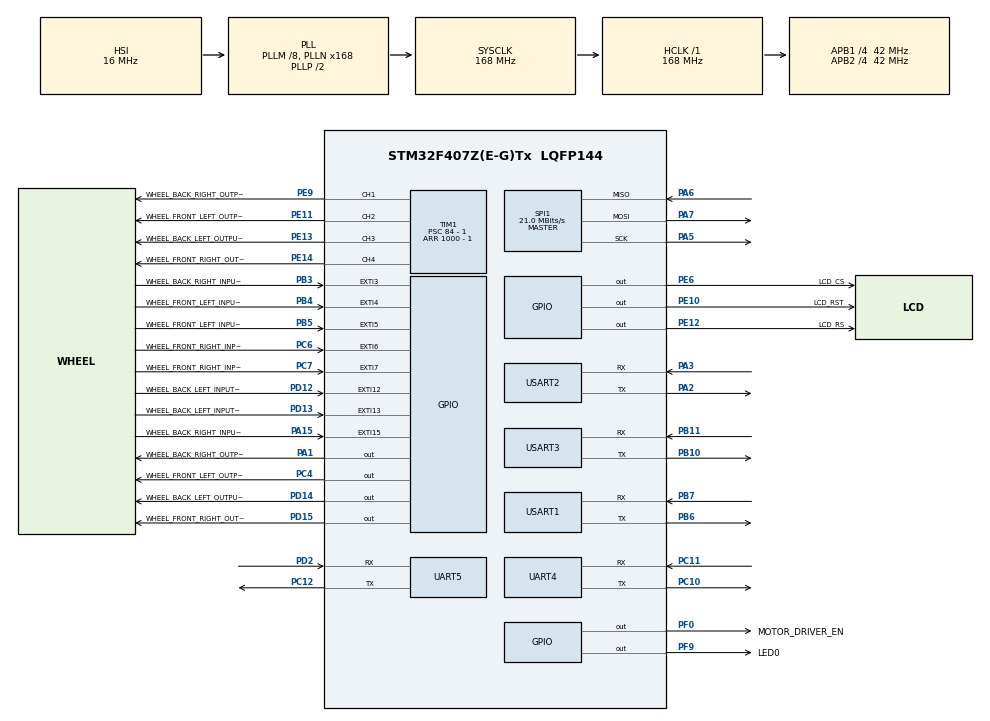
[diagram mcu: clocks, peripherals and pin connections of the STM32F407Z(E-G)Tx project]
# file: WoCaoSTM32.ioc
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Mcu.Family=STM32F4
Mcu.Name=STM32F407Z(E-G)Tx
Mcu.Package=LQFP144
NVIC.EXTI15_10_IRQn=true\:1\:0\:true\:false\:true\:true\:true
NVIC.EXTI3_IRQn=true\:1\:0\:true\:false\:true\:true\:true
NVIC.EXTI4_IRQn=true\:1\:0\:true\:false\:true\:true\:true
NVIC.EXTI9_5_IRQn=true\:1\:0\:true\:false\:true\:true\:true
NVIC.PriorityGroup=NVIC_PRIORITYGROUP_4
NVIC.TIM6_DAC_IRQn=true\:0\:0\:false\:false\:true\:true\:true
NVIC.UART4_IRQn=true\:1\:0\:true\:false\:true\:true\:true
NVIC.UART5_IRQn=true\:1\:0\:true\:false\:true\:true\:true
NVIC.USART1_IRQn=true\:1\:0\:true\:false\:true\:true\:true
NVIC.USART2_IRQn=true\:1\:0\:true\:false\:true\:true\:true
NVIC.USART3_IRQn=true\:0\:0\:false\:false\:true\:true\:true
PA1.GPIO_Label=WHEEL_BACK_RIGHT_OUTPUT_B
PA1.GPIO_Speed=GPIO_SPEED_FREQ_VERY_HIGH
PA1.Signal=GPIO_Output
PA13.Mode=Serial_Wire
PA13.Signal=SYS_JTMS-SWDIO
PA14.Mode=Serial_Wire
PA14.Signal=SYS_JTCK-SWCLK
PA15.GPIO_Label=WHEEL_BACK_RIGHT_INPUT_A
PA15.GPIO_ModeDefaultEXTI=GPIO_MODE_IT_RISING_FALLING
PA15.Signal=GPXTI15
PA2.Mode=Asynchronous
PA2.Signal=USART2_TX
PA3.Mode=Asynchronous
PA3.Signal=USART2_RX
PA5.Mode=Full_Duplex_Master
PA5.Signal=SPI1_SCK
PA6.Mode=Full_Duplex_Master
PA6.Signal=SPI1_MISO
PA7.Mode=Full_Duplex_Master
PA7.Signal=SPI1_MOSI
PB10.Mode=Asynchronous
PB10.Signal=USART3_TX
PB11.Mode=Asynchronous
PB11.Signal=USART3_RX
PB3.GPIO_Label=WHEEL_BACK_RIGHT_INPUT_B
PB3.GPIO_ModeDefaultEXTI=GPIO_MODE_IT_RISING_FALLING
PB3.Signal=GPXTI3
PB4.GPIO_Label=WHEEL_FRONT_LEFT_INPUT_A
PB4.GPIO_ModeDefaultEXTI=GPIO_MODE_IT_RISING_FALLING
PB4.GPIO_PuPd=GPIO_PULLDOWN
PB4.Signal=GPXTI4
PB5.GPIO_Label=WHEEL_FRONT_LEFT_INPUT_B
PB5.GPIO_ModeDefaultEXTI=GPIO_MODE_IT_RISING_FALLING
PB5.GPIO_PuPd=GPIO_PULLDOWN
PB5.Signal=GPXTI5
PB6.Mode=Asynchronous
PB6.Signal=USART1_TX
PB7.Mode=Asynchronous
PB7.Signal=USART1_RX
PC10.Mode=Asynchronous
PC10.Signal=UART4_TX
PC11.Mode=Asynchronous
PC11.Signal=UART4_RX
PC12.Mode=Asynchronous
PC12.Signal=UART5_TX
PC4.GPIO_Label=WHEEL_FRONT_LEFT_OUTPUT_B
PC4.GPIO_Speed=GPIO_SPEED_FREQ_VERY_HIGH
PC4.Signal=GPIO_Output
PC6.GPIO_Label=WHEEL_FRONT_RIGHT_INPUT_A
PC6.GPIO_ModeDefaultEXTI=GPIO_MODE_IT_RISING_FALLING
PC6.GPIO_PuPd=GPIO_PULLDOWN
PC6.Signal=GPXTI6
PC7.GPIO_Label=WHEEL_FRONT_RIGHT_INPUT_B
PC7.GPIO_ModeDefaultEXTI=GPIO_MODE_IT_RISING_FALLING
PC7.GPIO_PuPd=GPIO_PULLDOWN
PC7.Signal=GPXTI7
PD12.GPIO_Label=WHEEL_BACK_LEFT_INPUT_A
PD12.GPIO_ModeDefaultEXTI=GPIO_MODE_IT_RISING_FALLING
PD12.GPIO_PuPd=GPIO_PULLDOWN
PD12.Signal=GPXTI12
PD13.GPIO_Label=WHEEL_BACK_LEFT_INPUT_B
PD13.GPIO_ModeDefaultEXTI=GPIO_MODE_IT_RISING_FALLING
PD13.GPIO_PuPd=GPIO_PULLDOWN
PD13.Signal=GPXTI13
PD14.GPIO_Label=WHEEL_BACK_LEFT_OUTPUT_B
PD14.GPIO_Speed=GPIO_SPEED_FREQ_VERY_HIGH
PD14.Signal=GPIO_Output
PD15.GPIO_Label=WHEEL_FRONT_RIGHT_OUTPUT_B
PD15.GPIO_Speed=GPIO_SPEED_FREQ_VERY_HIGH
PD15.Signal=GPIO_Output
PD2.Mode=Asynchronous
PD2.Signal=UART5_RX
PE10.GPIO_Label=LCD_RST
PE10.GPIO_Speed=GPIO_SPEED_FREQ_VERY_HIGH
PE10.Signal=GPIO_Output
PE11.GPIO_Label=WHEEL_FRONT_LEFT_OUTPUT_A
PE11.GPIO_Speed=GPIO_SPEED_FREQ_VERY_HIGH
PE11.Signal=S_TIM1_CH2
PE12.GPIO_Label=LCD_RS
PE12.GPIO_Speed=GPIO_SPEED_FREQ_VERY_HIGH
PE12.Signal=GPIO_Output
PE13.GPIO_Label=WHEEL_BACK_LEFT_OUTPUT_A
PE13.GPIO_Speed=GPIO_SPEED_FREQ_VERY_HIGH
PE13.Signal=S_TIM1_CH3
PE14.GPIO_Label=WHEEL_FRONT_RIGHT_OUTPUT_A
PE14.GPIO_Speed=GPIO_SPEED_FREQ_VERY_HIGH
PE14.Signal=S_TIM1_CH4
PE6.GPIO_Label=LCD_CS
PE6.GPIO_Speed=GPIO_SPEED_FREQ_VERY_HIGH
PE6.Signal=GPIO_Output
PE9.GPIO_Label=WHEEL_BACK_RIGHT_OUTPUT_A
PE9.GPIO_Speed=GPIO_SPEED_FREQ_VERY_HIGH
PE9.Signal=S_TIM1_CH1
PF0.GPIO_Label=MOTOR_DRIVER_EN
PF0.GPIO_Speed=GPIO_SPEED_FREQ_VERY_HIGH
PF0.Signal=GPIO_Output
PF9.GPIO_Label=LED0
PF9.GPIO_Speed=GPIO_SPEED_FREQ_VERY_HIGH
PF9.Signal=GPIO_Output
PH0-OSC_IN.Mode=HSE-External-Oscillator
PH0-OSC_IN.Signal=RCC_OSC_IN
PH1-OSC_OUT.Mode=HSE-External-Oscillator
PH1-OSC_OUT.Signal=RCC_OSC_OUT
ProjectManager.HeapSize=0x1000
ProjectManager.StackSize=0x1000
ProjectManager.TargetToolchain=STM32CubeIDE
RCC.48MHZClocksFreq_Value=84000000
RCC.AHBFreq_Value=168000000
RCC.APB1CLKDivider=RCC_HCLK_DIV4
RCC.APB1Freq_Value=42000000
RCC.APB1TimFreq_Value=84000000
RCC.APB2CLKDivider=RCC_HCLK_DIV4
RCC.APB2Freq_Value=42000000
RCC.APB2TimFreq_Value=84000000
RCC.CortexFreq_Value=168000000
RCC.HCLKFreq_Value=168000000
RCC.HSE_VALUE=25000000
RCC.HSI_VALUE=16000000
RCC.LSE_VALUE=32768
RCC.PLLM=8
RCC.PLLN=168
RCC.SYSCLKFreq_VALUE=168000000
RCC.SYSCLKSource=RCC_SYSCLKSOURCE_PLLCLK
RCC.VCOOutputFreq_Value=336000000
SH.S_TIM1_CH1.0=TIM1_CH1,PWM Generation1 CH1
SH.S_TIM1_CH2.0=TIM1_CH2,PWM Generation2 CH2
SH.S_TIM1_CH3.0=TIM1_CH3,PWM Generation3 CH3
SH.S_TIM1_CH4.0=TIM1_CH4,PWM Generation4 CH4
SPI1.CalculateBaudRate=21.0 MBits/s
SPI1.Direction=SPI_DIRECTION_2LINES
SPI1.Mode=SPI_MODE_MASTER
SPI1.VirtualType=VM_MASTER
TIM1.Channel-PWM\ Generation1\ CH1=TIM_CHANNEL_1
TIM1.Channel-PWM\ Generation2\ CH2=TIM_CHANNEL_2
TIM1.Channel-PWM\ Generation3\ CH3=TIM_CHANNEL_3
TIM1.Channel-PWM\ Generation4\ CH4=TIM_CHANNEL_4
TIM1.Period=1000 - 1
TIM1.Prescaler=84 - 1
TIM6.Period=1000 - 1
TIM6.Prescaler=84 - 1
UART4.VirtualMode=Asynchronous
UART5.VirtualMode=Asynchronous
USART1.VirtualMode=VM_ASYNC
USART2.VirtualMode=VM_ASYNC
USART3.VirtualMode=VM_ASYNC
VP_TIM1_VS_ClockSourceINT.Mode=Internal
VP_TIM6_VS_ClockSourceINT.Mode=Enable_Timer
board=custom

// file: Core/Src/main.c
/* USER CODE BEGIN Header */
/**
  ******************************************************************************
  * @file           : main.c
  * @brief          : Main program body
  ******************************************************************************
  * @attention
  *
  * Copyright (c) 2023 STMicroelectronics.
  * All rights reserved.
  *
  * This software is licensed under terms that can be found in the LICENSE file
  * in the root directory of this software component.
  * If no LICENSE file comes with this software, it is provided AS-IS.
  *
  ******************************************************************************
  */
#include <stdio.h>
#include <string.h>
#include "RobotMain.h"

/* USER CODE END Header */
#include "main.h"

SPI_HandleTypeDef hspi1;

TIM_HandleTypeDef htim1;
TIM_HandleTypeDef htim6;

UART_HandleTypeDef huart4;
UART_HandleTypeDef huart5;
UART_HandleTypeDef huart1;
UART_HandleTypeDef huart2;
UART_HandleTypeDef huart3;

void SystemClock_Config(void);
static void MX_GPIO_Init(void);
static void MX_TIM1_Init(void);
static void MX_TIM6_Init(void);
static void MX_USART1_UART_Init(void);
static void MX_USART3_UART_Init(void);
static void MX_USART2_UART_Init(void);
static void MX_UART5_Init(void);
static void MX_SPI1_Init(void);
static void MX_UART4_Init(void);

int main(void)
{

  /* MCU Configuration--------------------------------------------------------*/

  /* Reset of all peripherals, Initializes the Flash interface and the Systick. */
  HAL_Init();

  /* Configure the system clock */
  SystemClock_Config();

  /* Initialize all configured peripherals */
  MX_GPIO_Init();
  MX_TIM1_Init();
  MX_TIM6_Init();
  MX_USART1_UART_Init();
  MX_USART3_UART_Init();
  MX_USART2_UART_Init();
  MX_UART5_Init();
  MX_SPI1_Init();
  MX_UART4_Init();
  /* USER CODE BEGIN 2 */

    HAL_Delay(1000);

    RobotMain();

  /* USER CODE END 2 */

  /* Infinite loop */
  /* USER CODE BEGIN WHILE */
  while (1)
  {
      HAL_GPIO_TogglePin(GPIOF, GPIO_PIN_9);
      HAL_Delay(100);

    /* USER CODE END WHILE */

  }
}

void SystemClock_Config(void)
{
  RCC_OscInitTypeDef RCC_OscInitStruct = {0};
  RCC_ClkInitTypeDef RCC_ClkInitStruct = {0};

  /** Configure the main internal regulator output voltage
  */
  __HAL_RCC_PWR_CLK_ENABLE();
  __HAL_PWR_VOLTAGESCALING_CONFIG(PWR_REGULATOR_VOLTAGE_SCALE1);
  /** Initializes the RCC Oscillators according to the specified parameters
  * in the RCC_OscInitTypeDef structure.
  */
  RCC_OscInitStruct.OscillatorType = RCC_OSCILLATORTYPE_HSI;
  RCC_OscInitStruct.HSIState = RCC_HSI_ON;
  RCC_OscInitStruct.HSICalibrationValue = RCC_HSICALIBRATION_DEFAULT;
  RCC_OscInitStruct.PLL.PLLState = RCC_PLL_ON;
  RCC_OscInitStruct.PLL.PLLSource = RCC_PLLSOURCE_HSI;
  RCC_OscInitStruct.PLL.PLLM = 8;
  RCC_OscInitStruct.PLL.PLLN = 168;
  RCC_OscInitStruct.PLL.PLLP = RCC_PLLP_DIV2;
  RCC_OscInitStruct.PLL.PLLQ = 4;
  if (HAL_RCC_OscConfig(&RCC_OscInitStruct) != HAL_OK)
  {
    Error_Handler();
  }
  /** Initializes the CPU, AHB and APB buses clocks
  */
  RCC_ClkInitStruct.ClockType = RCC_CLOCKTYPE_HCLK|RCC_CLOCKTYPE_SYSCLK
                              |RCC_CLOCKTYPE_PCLK1|RCC_CLOCKTYPE_PCLK2;
  RCC_ClkInitStruct.SYSCLKSource = RCC_SYSCLKSOURCE_PLLCLK;
  RCC_ClkInitStruct.AHBCLKDivider = RCC_SYSCLK_DIV1;
  RCC_ClkInitStruct.APB1CLKDivider = RCC_HCLK_DIV4;
  RCC_ClkInitStruct.APB2CLKDivider = RCC_HCLK_DIV4;

  if (HAL_RCC_ClockConfig(&RCC_ClkInitStruct, FLASH_LATENCY_5) != HAL_OK)
  {
    Error_Handler();
  }
}

static void MX_SPI1_Init(void)
{

  /* SPI1 parameter configuration*/
  hspi1.Instance = SPI1;
  hspi1.Init.Mode = SPI_MODE_MASTER;
  hspi1.Init.Direction = SPI_DIRECTION_2LINES;
  hspi1.Init.DataSize = SPI_DATASIZE_8BIT;
  hspi1.Init.CLKPolarity = SPI_POLARITY_LOW;
  hspi1.Init.CLKPhase = SPI_PHASE_1EDGE;
  hspi1.Init.NSS = SPI_NSS_SOFT;
  hspi1.Init.BaudRatePrescaler = SPI_BAUDRATEPRESCALER_2;
  hspi1.Init.FirstBit = SPI_FIRSTBIT_MSB;
  hspi1.Init.TIMode = SPI_TIMODE_DISABLE;
  hspi1.Init.CRCCalculation = SPI_CRCCALCULATION_DISABLE;
  hspi1.Init.CRCPolynomial = 10;
  if (HAL_SPI_Init(&hspi1) != HAL_OK)
  {
    Error_Handler();
  }

}

static void MX_TIM1_Init(void)
{

  TIM_ClockConfigTypeDef sClockSourceConfig = {0};
  TIM_MasterConfigTypeDef sMasterConfig = {0};
  TIM_OC_InitTypeDef sConfigOC = {0};
  TIM_BreakDeadTimeConfigTypeDef sBreakDeadTimeConfig = {0};

  htim1.Instance = TIM1;
  htim1.Init.Prescaler = 84 - 1;
  htim1.Init.CounterMode = TIM_COUNTERMODE_UP;
  htim1.Init.Period = 1000 - 1;
  htim1.Init.ClockDivision = TIM_CLOCKDIVISION_DIV1;
  htim1.Init.RepetitionCounter = 0;
  htim1.Init.AutoReloadPreload = TIM_AUTORELOAD_PRELOAD_DISABLE;
  if (HAL_TIM_Base_Init(&htim1) != HAL_OK)
  {
    Error_Handler();
  }
  sClockSourceConfig.ClockSource = TIM_CLOCKSOURCE_INTERNAL;
  if (HAL_TIM_ConfigClockSource(&htim1, &sClockSourceConfig) != HAL_OK)
  {
    Error_Handler();
  }
  if (HAL_TIM_PWM_Init(&htim1) != HAL_OK)
  {
    Error_Handler();
  }
  sMasterConfig.MasterOutputTrigger = TIM_TRGO_RESET;
  sMasterConfig.MasterSlaveMode = TIM_MASTERSLAVEMODE_DISABLE;
  if (HAL_TIMEx_MasterConfigSynchronization(&htim1, &sMasterConfig) != HAL_OK)
  {
    Error_Handler();
  }
  sConfigOC.OCMode = TIM_OCMODE_PWM1;
  sConfigOC.Pulse = 0;
  sConfigOC.OCPolarity = TIM_OCPOLARITY_HIGH;
  sConfigOC.OCNPolarity = TIM_OCNPOLARITY_HIGH;
  sConfigOC.OCFastMode = TIM_OCFAST_DISABLE;
  sConfigOC.OCIdleState = TIM_OCIDLESTATE_RESET;
  sConfigOC.OCNIdleState = TIM_OCNIDLESTATE_RESET;
  if (HAL_TIM_PWM_ConfigChannel(&htim1, &sConfigOC, TIM_CHANNEL_1) != HAL_OK)
  {
    Error_Handler();
  }
  if (HAL_TIM_PWM_ConfigChannel(&htim1, &sConfigOC, TIM_CHANNEL_2) != HAL_OK)
  {
    Error_Handler();
  }
  if (HAL_TIM_PWM_ConfigChannel(&htim1, &sConfigOC, TIM_CHANNEL_3) != HAL_OK)
  {
    Error_Handler();
  }
  if (HAL_TIM_PWM_ConfigChannel(&htim1, &sConfigOC, TIM_CHANNEL_4) != HAL_OK)
  {
    Error_Handler();
  }
  sBreakDeadTimeConfig.OffStateRunMode = TIM_OSSR_DISABLE;
  sBreakDeadTimeConfig.OffStateIDLEMode = TIM_OSSI_DISABLE;
  sBreakDeadTimeConfig.LockLevel = TIM_LOCKLEVEL_OFF;
  sBreakDeadTimeConfig.DeadTime = 0;
  sBreakDeadTimeConfig.BreakState = TIM_BREAK_DISABLE;
  sBreakDeadTimeConfig.BreakPolarity = TIM_BREAKPOLARITY_HIGH;
  sBreakDeadTimeConfig.AutomaticOutput = TIM_AUTOMATICOUTPUT_DISABLE;
  if (HAL_TIMEx_ConfigBreakDeadTime(&htim1, &sBreakDeadTimeConfig) != HAL_OK)
  {
    Error_Handler();
  }
  HAL_TIM_MspPostInit(&htim1);

}

static void MX_TIM6_Init(void)
{

  TIM_MasterConfigTypeDef sMasterConfig = {0};

  htim6.Instance = TIM6;
  htim6.Init.Prescaler = 84 - 1;
  htim6.Init.CounterMode = TIM_COUNTERMODE_UP;
  htim6.Init.Period = 1000 - 1;
  htim6.Init.AutoReloadPreload = TIM_AUTORELOAD_PRELOAD_DISABLE;
  if (HAL_TIM_Base_Init(&htim6) != HAL_OK)
  {
    Error_Handler();
  }
  sMasterConfig.MasterOutputTrigger = TIM_TRGO_RESET;
  sMasterConfig.MasterSlaveMode = TIM_MASTERSLAVEMODE_DISABLE;
  if (HAL_TIMEx_MasterConfigSynchronization(&htim6, &sMasterConfig) != HAL_OK)
  {
    Error_Handler();
  }

}

static void MX_UART4_Init(void)
{

  huart4.Instance = UART4;
  huart4.Init.BaudRate = 115200;
  huart4.Init.WordLength = UART_WORDLENGTH_8B;
  huart4.Init.StopBits = UART_STOPBITS_1;
  huart4.Init.Parity = UART_PARITY_NONE;
  huart4.Init.Mode = UART_MODE_TX_RX;
  huart4.Init.HwFlowCtl = UART_HWCONTROL_NONE;
  huart4.Init.OverSampling = UART_OVERSAMPLING_16;
  if (HAL_UART_Init(&huart4) != HAL_OK)
  {
    Error_Handler();
  }

}

static void MX_UART5_Init(void)
{

  huart5.Instance = UART5;
  huart5.Init.BaudRate = 115200;
  huart5.Init.WordLength = UART_WORDLENGTH_8B;
  huart5.Init.StopBits = UART_STOPBITS_1;
  huart5.Init.Parity = UART_PARITY_NONE;
  huart5.Init.Mode = UART_MODE_TX_RX;
  huart5.Init.HwFlowCtl = UART_HWCONTROL_NONE;
  huart5.Init.OverSampling = UART_OVERSAMPLING_16;
  if (HAL_UART_Init(&huart5) != HAL_OK)
  {
    Error_Handler();
  }

}

static void MX_USART1_UART_Init(void)
{

  huart1.Instance = USART1;
  huart1.Init.BaudRate = 115200;
  huart1.Init.WordLength = UART_WORDLENGTH_8B;
  huart1.Init.StopBits = UART_STOPBITS_1;
  huart1.Init.Parity = UART_PARITY_NONE;
  huart1.Init.Mode = UART_MODE_TX_RX;
  huart1.Init.HwFlowCtl = UART_HWCONTROL_NONE;
  huart1.Init.OverSampling = UART_OVERSAMPLING_16;
  if (HAL_UART_Init(&huart1) != HAL_OK)
  {
    Error_Handler();
  }

}

static void MX_USART2_UART_Init(void)
{

  huart2.Instance = USART2;
  huart2.Init.BaudRate = 115200;
  huart2.Init.WordLength = UART_WORDLENGTH_8B;
  huart2.Init.StopBits = UART_STOPBITS_1;
  huart2.Init.Parity = UART_PARITY_NONE;
  huart2.Init.Mode = UART_MODE_TX_RX;
  huart2.Init.HwFlowCtl = UART_HWCONTROL_NONE;
  huart2.Init.OverSampling = UART_OVERSAMPLING_16;
  if (HAL_UART_Init(&huart2) != HAL_OK)
  {
    Error_Handler();
  }

}

static void MX_USART3_UART_Init(void)
{

  huart3.Instance = USART3;
  huart3.Init.BaudRate = 115200;
  huart3.Init.WordLength = UART_WORDLENGTH_8B;
  huart3.Init.StopBits = UART_STOPBITS_1;
  huart3.Init.Parity = UART_PARITY_NONE;
  huart3.Init.Mode = UART_MODE_TX_RX;
  huart3.Init.HwFlowCtl = UART_HWCONTROL_NONE;
  huart3.Init.OverSampling = UART_OVERSAMPLING_16;
  if (HAL_UART_Init(&huart3) != HAL_OK)
  {
    Error_Handler();
  }

}

static void MX_GPIO_Init(void)
{
  GPIO_InitTypeDef GPIO_InitStruct = {0};

  /* GPIO Ports Clock Enable */
  __HAL_RCC_GPIOE_CLK_ENABLE();
  __HAL_RCC_GPIOF_CLK_ENABLE();
  __HAL_RCC_GPIOH_CLK_ENABLE();
  __HAL_RCC_GPIOA_CLK_ENABLE();
  __HAL_RCC_GPIOC_CLK_ENABLE();
  __HAL_RCC_GPIOB_CLK_ENABLE();
  __HAL_RCC_GPIOD_CLK_ENABLE();

  /*Configure GPIO pin Output Level */
  HAL_GPIO_WritePin(GPIOE, LCD_CS_Pin|LCD_RST_Pin|LCD_RS_Pin, GPIO_PIN_RESET);

  /*Configure GPIO pin Output Level */
  HAL_GPIO_WritePin(GPIOF, MOTOR_DRIVER_EN_Pin|LED0_Pin, GPIO_PIN_RESET);

  /*Configure GPIO pin Output Level */
  HAL_GPIO_WritePin(WHEEL_BACK_RIGHT_OUTPUT_B_GPIO_Port, WHEEL_BACK_RIGHT_OUTPUT_B_Pin, GPIO_PIN_RESET);

  /*Configure GPIO pin Output Level */
  HAL_GPIO_WritePin(WHEEL_FRONT_LEFT_OUTPUT_B_GPIO_Port, WHEEL_FRONT_LEFT_OUTPUT_B_Pin, GPIO_PIN_RESET);

  /*Configure GPIO pin Output Level */
  HAL_GPIO_WritePin(GPIOD, WHEEL_BACK_LEFT_OUTPUT_B_Pin|WHEEL_FRONT_RIGHT_OUTPUT_B_Pin, GPIO_PIN_RESET);

  /*Configure GPIO pins : LCD_CS_Pin LCD_RST_Pin LCD_RS_Pin */
  GPIO_InitStruct.Pin = LCD_CS_Pin|LCD_RST_Pin|LCD_RS_Pin;
  GPIO_InitStruct.Mode = GPIO_MODE_OUTPUT_PP;
  GPIO_InitStruct.Pull = GPIO_NOPULL;
  GPIO_InitStruct.Speed = GPIO_SPEED_FREQ_VERY_HIGH;
  HAL_GPIO_Init(GPIOE, &GPIO_InitStruct);

  /*Configure GPIO pins : MOTOR_DRIVER_EN_Pin LED0_Pin */
  GPIO_InitStruct.Pin = MOTOR_DRIVER_EN_Pin|LED0_Pin;
  GPIO_InitStruct.Mode = GPIO_MODE_OUTPUT_PP;
  GPIO_InitStruct.Pull = GPIO_NOPULL;
  GPIO_InitStruct.Speed = GPIO_SPEED_FREQ_VERY_HIGH;
  HAL_GPIO_Init(GPIOF, &GPIO_InitStruct);

  /*Configure GPIO pin : WHEEL_BACK_RIGHT_OUTPUT_B_Pin */
  GPIO_InitStruct.Pin = WHEEL_BACK_RIGHT_OUTPUT_B_Pin;
  GPIO_InitStruct.Mode = GPIO_MODE_OUTPUT_PP;
  GPIO_InitStruct.Pull = GPIO_NOPULL;
  GPIO_InitStruct.Speed = GPIO_SPEED_FREQ_VERY_HIGH;
  HAL_GPIO_Init(WHEEL_BACK_RIGHT_OUTPUT_B_GPIO_Port, &GPIO_InitStruct);

  /*Configure GPIO pin : WHEEL_FRONT_LEFT_OUTPUT_B_Pin */
  GPIO_InitStruct.Pin = WHEEL_FRONT_LEFT_OUTPUT_B_Pin;
  GPIO_InitStruct.Mode = GPIO_MODE_OUTPUT_PP;
  GPIO_InitStruct.Pull = GPIO_NOPULL;
  GPIO_InitStruct.Speed = GPIO_SPEED_FREQ_VERY_HIGH;
  HAL_GPIO_Init(WHEEL_FRONT_LEFT_OUTPUT_B_GPIO_Port, &GPIO_InitStruct);

  /*Configure GPIO pins : WHEEL_BACK_LEFT_INPUT_A_Pin WHEEL_BACK_LEFT_INPUT_B_Pin */
  GPIO_InitStruct.Pin = WHEEL_BACK_LEFT_INPUT_A_Pin|WHEEL_BACK_LEFT_INPUT_B_Pin;
  GPIO_InitStruct.Mode = GPIO_MODE_IT_RISING_FALLING;
  GPIO_InitStruct.Pull = GPIO_PULLDOWN;
  HAL_GPIO_Init(GPIOD, &GPIO_InitStruct);

  /*Configure GPIO pins : WHEEL_BACK_LEFT_OUTPUT_B_Pin WHEEL_FRONT_RIGHT_OUTPUT_B_Pin */
  GPIO_InitStruct.Pin = WHEEL_BACK_LEFT_OUTPUT_B_Pin|WHEEL_FRONT_RIGHT_OUTPUT_B_Pin;
  GPIO_InitStruct.Mode = GPIO_MODE_OUTPUT_PP;
  GPIO_InitStruct.Pull = GPIO_NOPULL;
  GPIO_InitStruct.Speed = GPIO_SPEED_FREQ_VERY_HIGH;
  HAL_GPIO_Init(GPIOD, &GPIO_InitStruct);

  /*Configure GPIO pins : WHEEL_FRONT_RIGHT_INPUT_A_Pin WHEEL_FRONT_RIGHT_INPUT_B_Pin */
  GPIO_InitStruct.Pin = WHEEL_FRONT_RIGHT_INPUT_A_Pin|WHEEL_FRONT_RIGHT_INPUT_B_Pin;
  GPIO_InitStruct.Mode = GPIO_MODE_IT_RISING_FALLING;
  GPIO_InitStruct.Pull = GPIO_PULLDOWN;
  HAL_GPIO_Init(GPIOC, &GPIO_InitStruct);

  /*Configure GPIO pin : WHEEL_BACK_RIGHT_INPUT_A_Pin */
  GPIO_InitStruct.Pin = WHEEL_BACK_RIGHT_INPUT_A_Pin;
  GPIO_InitStruct.Mode = GPIO_MODE_IT_RISING_FALLING;
  GPIO_InitStruct.Pull = GPIO_NOPULL;
  HAL_GPIO_Init(WHEEL_BACK_RIGHT_INPUT_A_GPIO_Port, &GPIO_InitStruct);

  /*Configure GPIO pin : WHEEL_BACK_RIGHT_INPUT_B_Pin */
  GPIO_InitStruct.Pin = WHEEL_BACK_RIGHT_INPUT_B_Pin;
  GPIO_InitStruct.Mode = GPIO_MODE_IT_RISING_FALLING;
  GPIO_InitStruct.Pull = GPIO_NOPULL;
  HAL_GPIO_Init(WHEEL_BACK_RIGHT_INPUT_B_GPIO_Port, &GPIO_InitStruct);

  /*Configure GPIO pins : WHEEL_FRONT_LEFT_INPUT_A_Pin WHEEL_FRONT_LEFT_INPUT_B_Pin */
  GPIO_InitStruct.Pin = WHEEL_FRONT_LEFT_INPUT_A_Pin|WHEEL_FRONT_LEFT_INPUT_B_Pin;
  GPIO_InitStruct.Mode = GPIO_MODE_IT_RISING_FALLING;
  GPIO_InitStruct.Pull = GPIO_PULLDOWN;
  HAL_GPIO_Init(GPIOB, &GPIO_InitStruct);

  /* EXTI interrupt init*/
  HAL_NVIC_SetPriority(EXTI3_IRQn, 1, 0);
  HAL_NVIC_EnableIRQ(EXTI3_IRQn);

  HAL_NVIC_SetPriority(EXTI4_IRQn, 1, 0);
  HAL_NVIC_EnableIRQ(EXTI4_IRQn);

  HAL_NVIC_SetPriority(EXTI9_5_IRQn, 1, 0);
  HAL_NVIC_EnableIRQ(EXTI9_5_IRQn);

  HAL_NVIC_SetPriority(EXTI15_10_IRQn, 1, 0);
  HAL_NVIC_EnableIRQ(EXTI15_10_IRQn);

}

void Error_Handler(void)
{
  __disable_irq();
  while (1)
  {
  }
}
